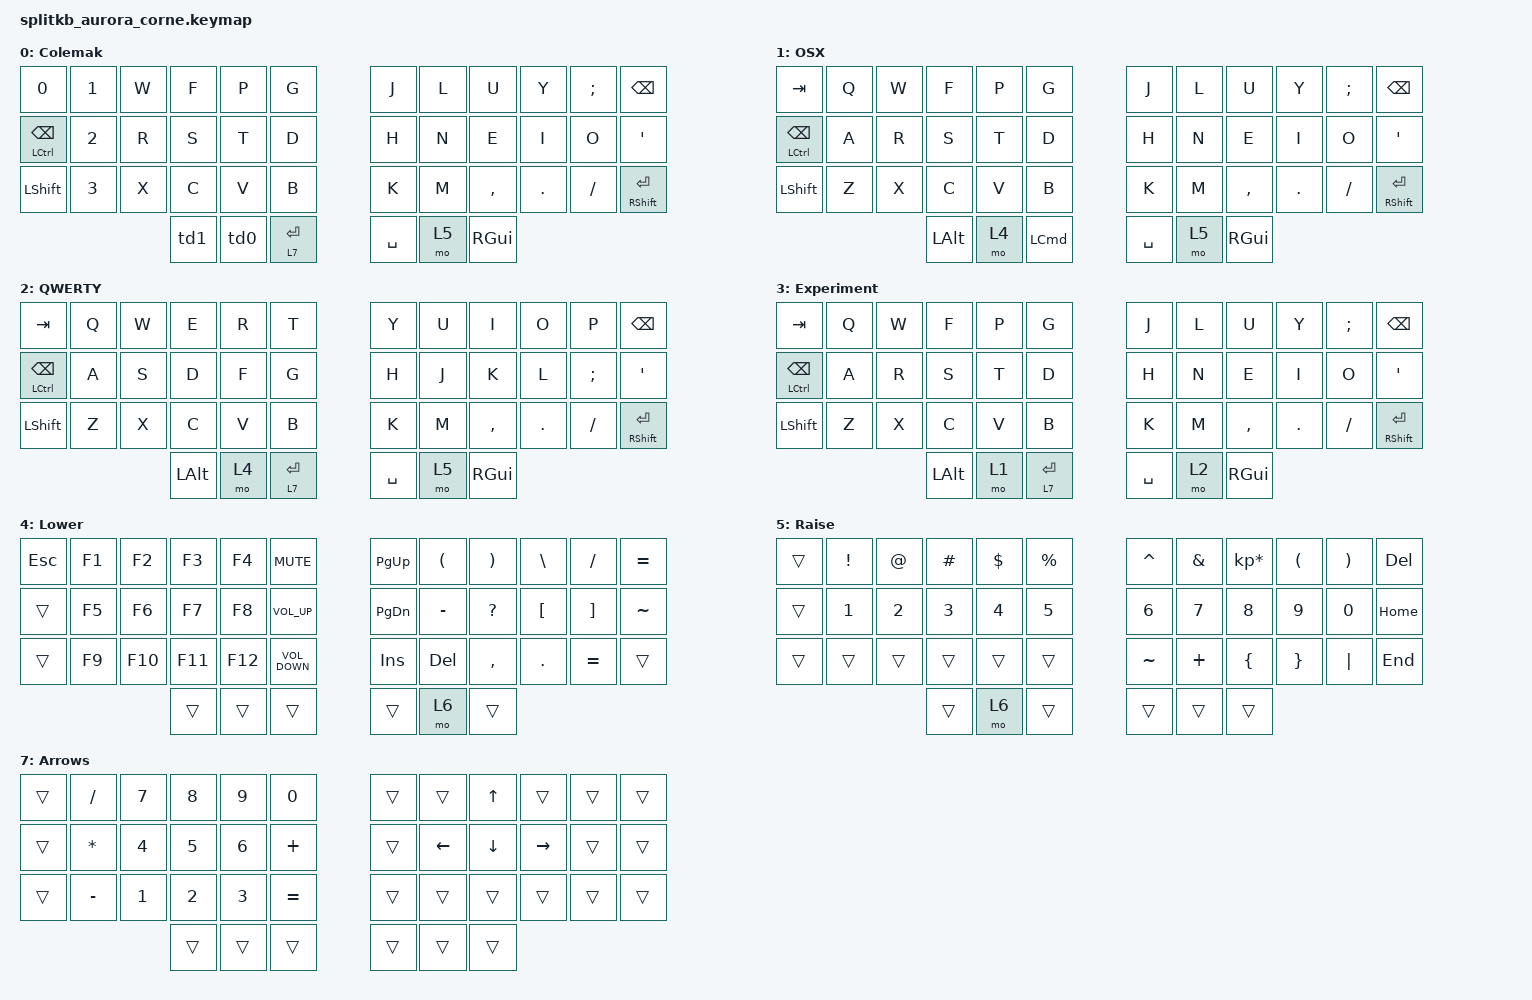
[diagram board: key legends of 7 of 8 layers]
/*
 * Copyright (c) 2020 The ZMK Contributors
 *
 * SPDX-License-Identifier: MIT
 */

#include <behaviors.dtsi>
#include <dt-bindings/zmk/keys.h>
#include <dt-bindings/zmk/bt.h>


/ {
    behaviors {
        td1: tap_dance_1 {
            compatible = "zmk,behavior-tap-dance";
            label = "TAP_DANCE_1";
            #binding-cells = <0>;
            tapping-term-ms = <300>;
            bindings = <&kp LEFT_CONTROL>, <&kp LEFT_ALT>, <&kp LEFT_GUI>;
        };
    };

    keymap {
        compatible = "zmk,keymap";

        default_layer {
            bindings = <
                &td1
            >;
        };
    };
};

/ {
    behaviors {
        td0: tap_dance_0 {
            compatible = "zmk,behavior-tap-dance";
            label = "TAP_DANCE_0";
            #binding-cells = <0>;
            tapping-term-ms = <300>;
            bindings = <&mo 4>, <&mo 7>;
        };
    };

    keymap {
        compatible = "zmk,keymap";

        default_layer {
            bindings = <
                &td0
            >;
        };
    };
};

#define DEFAULT      0
#define OSX          1
#define QWERTY       2
#define EXPERIMENTAL 3
#define LOWER        4
#define RAISE        5
#define BOTH         6
#define ARROWS       7

/ {
        keymap {
                compatible = "zmk,keymap";

                default_layer {
                        label = "Colemak";

// ┏━━━━━━━━━━━┏━━━━━━━━━━━┳━━━━━━━━━━━┳━━━━━━━━━━━┳━━━━━━━━━━━┳━━━━━━━━━━━┓   ┏━━━━━━━━━━━┳━━━━━━━━━━━┳━━━━━━━━━━━┳━━━━━━━━━━━┳━━━━━━━━━━━┓━━━━━━━━━━━┓
// ┃    Tab    ┃     Q     ┃     W     ┃     F     ┃     P     ┃     G     ┃   ┃     J     ┃     L     ┃     U     ┃     Y     ┃     ;     ┃    BkSp   ┃
// ┗━━━━━━━━━━━┣━━━━━━━━━━━╋━━━━━━━━━━━╋━━━━━━━━━━━╋━━━━━━━━━━━╋━━━━━━━━━━━┫   ┣━━━━━━━━━━━╋━━━━━━━━━━━╋━━━━━━━━━━━╋━━━━━━━━━━━╋━━━━━━━━━━━┫━━━━━━━━━━━┛
// ┃ Ctrl/BkSp ┃     A     ┃     R     ┃     S     ┃     T     ┃     D     ┃   ┃     H     ┃     N     ┃     E     ┃     I     ┃     O     ┃      '    ┃
// ┏━━━━━━━━━━━╋━━━━━━━━━━━╋━━━━━━━━━━━╋━━━━━━━━━━━╋━━━━━━━━━━━╋━━━━━━━━━━━┫   ┣━━━━━━━━━━━╋━━━━━━━━━━━╋━━━━━━━━━━━╋━━━━━━━━━━━╋━━━━━━━━━━━╋━━━━━━━━━━━┓
// ┃   Shift   ┃     Z     ┃     X     ┃     C     ┃     V     ┃     B     ┃   ┃     K     ┃     M     ┃     ,     ┃     .     ┃     /     ┃  Ent/Sft  ┃
// ┗━━━━━━━━━━━┻━━━━━━━━━━━┻━━━━━━━━━━━╋━━━━━━━━━━━╋━━━━━━━━━━━╋━━━━━━━━━━━┫   ┣━━━━━━━━━━━╋━━━━━━━━━━━╋━━━━━━━━━━━╋━━━━━━━━━━━┻━━━━━━━━━━━┻━━━━━━━━━━━┛
//                                     ┃Ctr/Alt/Win┃Lower/Arrow┃ Arrow/Ent ┃   ┃   Space   ┃   Raise   ┃    Win    ┃
//                                     ┗━━━━━━━━━━━┻━━━━━━━━━━━┻━━━━━━━━━━━┛   ┗━━━━━━━━━━━┻━━━━━━━━━━━┻━━━━━━━━━━━┛                        

                        bindings = <
&kp NUMBER_0                 &kp NUMBER_1   &kp W   &kp F          &kp P   &kp G                &kp J       &kp L   &kp U          &kp Y    &kp SEMI   &kp BACKSPACE
&mt LEFT_CONTROL BACKSPACE   &kp NUMBER_2   &kp R   &kp S          &kp T   &kp D                &kp H       &kp N   &kp E          &kp I    &kp O      &kp APOS
&kp LSHFT                    &kp NUMBER_3   &kp X   &kp C          &kp V   &kp B                &kp K       &kp M   &kp COMMA      &kp DOT  &kp FSLH   &mt RIGHT_SHIFT ENTER
                                             &td1        &td0    &lt 7 ENTER          &kp SPACE   &mo 5   &kp RIGHT_GUI
                        >;
                };
                osx_layer {
                        label = "OSX";
// ┏━━━━━━━━━━━┏━━━━━━━━━━━┳━━━━━━━━━━━┳━━━━━━━━━━━┳━━━━━━━━━━━┳━━━━━━━━━━━┓   ┏━━━━━━━━━━━┳━━━━━━━━━━━┳━━━━━━━━━━━┳━━━━━━━━━━━┳━━━━━━━━━━━┓━━━━━━━━━━━┓
// ┃    Tab    ┃     Q     ┃     W     ┃     F     ┃     P     ┃     G     ┃   ┃     J     ┃     L     ┃     U     ┃     Y     ┃     ;     ┃    BkSp   ┃
// ┗━━━━━━━━━━━┣━━━━━━━━━━━╋━━━━━━━━━━━╋━━━━━━━━━━━╋━━━━━━━━━━━╋━━━━━━━━━━━┫   ┣━━━━━━━━━━━╋━━━━━━━━━━━╋━━━━━━━━━━━╋━━━━━━━━━━━╋━━━━━━━━━━━┫━━━━━━━━━━━┛
// ┃ Ctrl/BkSp ┃     A     ┃     R     ┃     S     ┃     T     ┃     D     ┃   ┃     H     ┃     N     ┃     E     ┃     I     ┃     O     ┃      '    ┃
// ┏━━━━━━━━━━━╋━━━━━━━━━━━╋━━━━━━━━━━━╋━━━━━━━━━━━╋━━━━━━━━━━━╋━━━━━━━━━━━┫   ┣━━━━━━━━━━━╋━━━━━━━━━━━╋━━━━━━━━━━━╋━━━━━━━━━━━╋━━━━━━━━━━━╋━━━━━━━━━━━┓
// ┃   Shift   ┃     Z     ┃     X     ┃     C     ┃     V     ┃     B     ┃   ┃     K     ┃     M     ┃     ,     ┃     .     ┃     /     ┃  Ent/Sft  ┃
// ┗━━━━━━━━━━━┻━━━━━━━━━━━┻━━━━━━━━━━━╋━━━━━━━━━━━╋━━━━━━━━━━━╋━━━━━━━━━━━┫   ┣━━━━━━━━━━━╋━━━━━━━━━━━╋━━━━━━━━━━━╋━━━━━━━━━━━┻━━━━━━━━━━━┻━━━━━━━━━━━┛
//                                     ┃     Alt   ┃Lower/Arrow┃ Arrow/Ent ┃   ┃   Space   ┃   Raise   ┃    Win    ┃
//                                     ┗━━━━━━━━━━━┻━━━━━━━━━━━┻━━━━━━━━━━━┛   ┗━━━━━━━━━━━┻━━━━━━━━━━━┻━━━━━━━━━━━┛                        

// -----------------------------------------------------------------------------------------
// |  TAB |  Q  |  W  |  F  |  P  |  G  |   |  J  |  L   |  U  |  Y  |  ;  | BKSP |
// | CTBP |  A  |  R  |  S  |  T  |  D  |   |  H  |  N   |  E  |  I  |  O  |  '   |
// | SHFT |  Z  |  X  |  C  |  V  |  B  |   |  K  |  M   |  ,  |  .  |  /  | ETSF |
//                    | GUI | LWR | SPC |   | ENT | RSE  | ALT |
                        bindings = <
&kp TAB                      &kp Q   &kp W   &kp F          &kp P   &kp G                &kp J       &kp L   &kp U          &kp Y    &kp SEMI   &kp BACKSPACE
&mt LEFT_CONTROL BACKSPACE   &kp A   &kp R   &kp S          &kp T   &kp D                &kp H       &kp N   &kp E          &kp I    &kp O      &kp APOS
&kp LSHFT                    &kp Z   &kp X   &kp C          &kp V   &kp B                &kp K       &kp M   &kp COMMA      &kp DOT  &kp FSLH   &mt RIGHT_SHIFT ENTER
                                             &kp LEFT_ALT   &mo 4   &kp LCMD             &kp SPACE   &mo 5   &kp RIGHT_GUI
                        >;
                };
                qwerty_layer {
                        label = "QWERTY";
// -----------------------------------------------------------------------------------------
// |  TAB |  Q  |  W  |  E  |  R  |  T  |   |  Y  |  U   |  I  |  O  |  P  | BKSP |
// | CTBP |  A  |  S  |  D  |  F  |  G  |   |  H  |  J   |  K  |  L  |  ;  |  '   |
// | SHFT |  Z  |  X  |  C  |  V  |  B  |   |  N  |  M   |  ,  |  .  |  /  | ETSF |
//                    | GUI | LWR | SPC |   | ENT | RSE  | ALT |
                        bindings = <
&kp TAB                      &kp Q   &kp W   &kp E          &kp R   &kp T                &kp Y       &kp U   &kp I          &kp O    &kp P   &kp BACKSPACE
&mt LEFT_CONTROL BACKSPACE   &kp A   &kp S   &kp D          &kp F   &kp G                &kp H       &kp J   &kp K          &kp L    &kp SEMI      &kp APOS
&kp LSHFT                    &kp Z   &kp X   &kp C          &kp V   &kp B                &kp K       &kp M   &kp COMMA      &kp DOT  &kp FSLH   &mt RIGHT_SHIFT ENTER
                                             &kp LEFT_ALT   &mo 4   &lt 7 ENTER          &kp SPACE   &mo 5   &kp RIGHT_GUI
                        >;
                };
                experimental_layer {
                        label = "Experiment";
// -----------------------------------------------------------------------------------------
// |  TAB |  Q  |  W  |  F  |  P  |  G  |   |  J  |  L   |  U  |  Y  |  ;  | BKSP |
// | CTBP |  A  |  R  |  S  |  T  |  D  |   |  H  |  N   |  E  |  I  |  O  |  '   |
// | SHFT |  Z  |  X  |  C  |  V  |  B  |   |  K  |  M   |  ,  |  .  |  /  | ETSF |
//                    | GUI | LWR | SPC |   | ENT | RSE  | ALT |
                        bindings = <
&kp TAB                      &kp Q   &kp W   &kp F          &kp P   &kp G                &kp J       &kp L   &kp U          &kp Y    &kp SEMI   &kp BACKSPACE
&mt LEFT_CONTROL BACKSPACE   &kp A   &kp R   &kp S          &kp T   &kp D                &kp H       &kp N   &kp E          &kp I    &kp O      &kp APOS
&kp LSHFT                    &kp Z   &kp X   &kp C          &kp V   &kp B                &kp K       &kp M   &kp COMMA      &kp DOT  &kp FSLH   &mt RIGHT_SHIFT ENTER
                                             &kp LEFT_ALT   &mo 1   &lt 7 ENTER          &kp SPACE   &mo 2   &kp RIGHT_GUI
                        >;
                };
                lower_layer {
                        label = "Lower";
// -----------------------------------------------------------------------------------------
// |  TAB | F1 |  F2  |  F3 |  F4 |  MUTE |   | PGUP |  (  |  )  |  \  |  /  |   = |
// | BTCLR| F5 |  F6  |  F7 |  F8 |  Vol+ |   | PGDN |  -  |  ?  |  [  |  ]  |  ~  |      
// | SHFT | F9 |  F10 | F11 | F12 |  Vol- |   |INSERT| DEL |  ,  |  .  |  =  |     |
//                    | GUI |     | SPC |   | ENT |     | ALT |
                        bindings = <
&kp ESC  &kp F1   &kp F2   &kp F3   &kp F4    &kp K_MUTE                &kp PAGE_UP    &kp LPAR    &kp RPAR      &kp BACKSLASH  &kp SLASH  &kp EQUAL
&trans   &kp F5   &kp F6   &kp F7   &kp F8    &kp C_VOLUME_UP           &kp PAGE_DOWN  &kp MINUS   &kp QUESTION  &kp LBKT       &kp RBKT   &kp TILDE
&trans   &kp F9   &kp F10  &kp F11  &kp F12   &kp C_VOLUME_DOWN         &kp INS        &kp DELETE  &kp COMMA     &kp PERIOD     &kp EQUAL  &trans
                           &trans   &trans    &trans                    &trans         &mo 6       &trans
                        >;
                };

                raise_layer {
                        label = "Raise";
// -----------------------------------------------------------------------------------------
// |      |  !  |  @  |  #  |  $  |  %  |   |  ^  |  &  |  *  |  ( |  )  |  DEL  |
// |      |  1  |  2  |  3  |  4  |  5  |   |  6  |  7  |  8  |  9 |  0  |  HOME |
// |      |     |     |     |     |     |   |  ~  |  +  |  {  |  } |  |  |  END  | 
//                    | GUI |     | SPC |   | ENT |     | ALT |
                        bindings = <
 &trans  &kp EXCL      &kp AT        &kp HASH      &kp DLLR      &kp PRCNT             &kp CARET      &kp AMPS       &kp KP_MULTIPLY   &kp LPAR      &kp RPAR       &kp DELETE
 &trans  &kp NUMBER_1  &kp NUMBER_2  &kp NUMBER_3  &kp NUMBER_4  &kp NUMBER_5          &kp NUMBER_6   &kp NUMBER_7   &kp NUMBER_8      &kp NUMBER_9  &kp NUMBER_0   &kp HOME
 &trans  &trans        &trans        &trans        &trans        &trans                &kp TILDE      &kp PLUS       &kp LBRC          &kp RBRC      &kp PIPE       &kp END
                                     &trans        &mo 6         &trans                &trans         &trans         &trans
                             
                        >;
                };

                both_layer {
                        label = "Adjust";
// -----------------------------------------------------------------------------------------
// |  TAB | BOOT |    |     |  DEFAULT  |  BT0  |     |  BT3   | EXPER |     |     | BOOT |    |
// | CTRL |      |    |     |   OSX     |  BT1  |     |  BT4   |       |     |     |      |    |
// | SHFT |     |     |     |  QWERTY   |  BT2  |     |  BTCLR |       |     |     |      |    |
//                    | GUI |     | SPC |   | ENT |     | ALT |
                        bindings = <
&caps_word  &bootloader &trans  &trans  &to 0  &bt BT_SEL 0          &bt BT_SEL 3  &to 3   &trans  &trans  &bootloader &trans
&kp CAPS    &trans      &trans  &trans  &to 1  &bt BT_SEL 1          &bt BT_SEL 4  &to 4   &trans  &trans  &trans      &trans
&trans      &trans      &trans  &trans  &to 2  &bt BT_SEL 2          &bt BT_CLR    &trans  &trans  &trans  &trans
                                &trans  &trans &trans                &trans        &trans  &trans                                       
                                  
 >;
                };

                arrows_layer {
                        label = "Arrows";
// -----------------------------------------------------------------------------------------
// |  TAB |  /  |  7  |  8  |  9  |  0  |     |  ^  |  &  |  *  |  (  |  boot  | BKSP |
// | CTRL |  *  |  4  |  5  |  6  |  +  |     |  -  | LEFT |  DOWN  |  ]  |  \  |  `   |
// | SHFT |  -  |  1  |  2  |  3  |  =  |     |  _  |  +  |  {  |  }  | "|" |  ~   |
//                    | GUI |     | SPC |     | ENT |     | ALT |
                        bindings = <
 &trans  &kp SLASH  &kp NUMBER_7  &kp NUMBER_8  &kp NUMBER_9  &kp NUMBER_0      &trans    &trans    &kp UP     &trans     &trans  &trans
 &trans  &kp ASTRK  &kp NUMBER_4  &kp NUMBER_5  &kp NUMBER_6  &kp PLUS          &trans    &kp LEFT  &kp DOWN   &kp RIGHT  &trans  &trans
 &trans  &kp MINUS  &kp NUMBER_1  &kp NUMBER_2  &kp NUMBER_3  &kp EQUAL         &trans    &trans    &trans     &trans     &trans  &trans
                                  &trans        &trans        &trans            &trans    &trans    &trans                                        
                        >;
                };
        };
};
